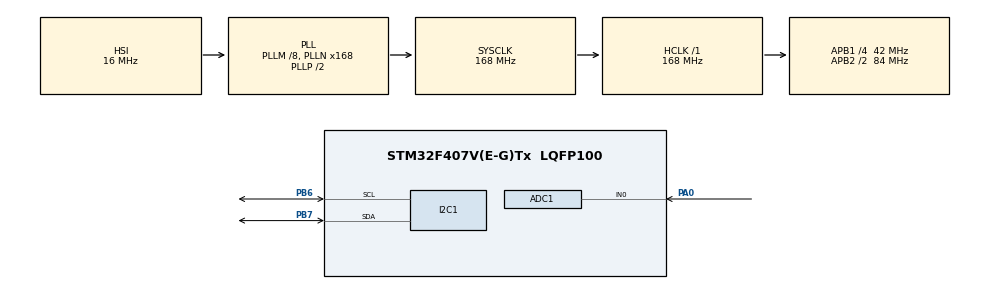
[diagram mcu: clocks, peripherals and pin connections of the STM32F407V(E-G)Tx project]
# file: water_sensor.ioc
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ADC1.Channel-0\#ChannelRegularConversion=ADC_CHANNEL_0
ADC1.NbrOfConversionFlag=1
ADC1.Rank-0\#ChannelRegularConversion=1
ADC1.SamplingTime-0\#ChannelRegularConversion=ADC_SAMPLETIME_3CYCLES
ADC1.master=1
Mcu.Family=STM32F4
Mcu.Name=STM32F407V(E-G)Tx
Mcu.Package=LQFP100
NVIC.PriorityGroup=NVIC_PRIORITYGROUP_4
PA0-WKUP.Signal=ADCx_IN0
PA13.Mode=Serial_Wire
PA13.Signal=SYS_JTMS-SWDIO
PA14.Mode=Serial_Wire
PA14.Signal=SYS_JTCK-SWCLK
PB6.Mode=I2C
PB6.Signal=I2C1_SCL
PB7.Mode=I2C
PB7.Signal=I2C1_SDA
PH0-OSC_IN.Mode=HSE-External-Oscillator
PH0-OSC_IN.Signal=RCC_OSC_IN
PH1-OSC_OUT.Mode=HSE-External-Oscillator
PH1-OSC_OUT.Signal=RCC_OSC_OUT
ProjectManager.HeapSize=0x200
ProjectManager.StackSize=0x400
ProjectManager.TargetToolchain=STM32CubeIDE
RCC.48MHZClocksFreq_Value=84000000
RCC.AHBFreq_Value=168000000
RCC.APB1CLKDivider=RCC_HCLK_DIV4
RCC.APB1Freq_Value=42000000
RCC.APB1TimFreq_Value=84000000
RCC.APB2CLKDivider=RCC_HCLK_DIV2
RCC.APB2Freq_Value=84000000
RCC.APB2TimFreq_Value=168000000
RCC.CortexFreq_Value=168000000
RCC.HCLKFreq_Value=168000000
RCC.HSE_VALUE=25000000
RCC.HSI_VALUE=16000000
RCC.LSE_VALUE=32768
RCC.PLLM=8
RCC.PLLN=168
RCC.SYSCLKFreq_VALUE=168000000
RCC.SYSCLKSource=RCC_SYSCLKSOURCE_PLLCLK
RCC.VCOOutputFreq_Value=336000000
SH.ADCx_IN0.0=ADC1_IN0,IN0
board=custom

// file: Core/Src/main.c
/* USER CODE BEGIN Header */
/**
  ******************************************************************************
  * @file           : main.c
  * @brief          : Main program body
  ******************************************************************************
  * @attention
  *
  * Copyright (c) 2024 STMicroelectronics.
  * All rights reserved.
  *
  * This software is licensed under terms that can be found in the LICENSE file
  * in the root directory of this software component.
  * If no LICENSE file comes with this software, it is provided AS-IS.
  *
  ******************************************************************************
  */
/* USER CODE END Header */
#include "main.h"
#include "i2c-lcd.h"
#include <stdio.h>

ADC_HandleTypeDef hadc1;

I2C_HandleTypeDef hi2c1;

/* USER CODE BEGIN PV */
uint32_t adc_value = 0;  // Valeur convertie de l'ADC
float water_level = 0.0; // Niveau d'eau en pourcentage
char buffer[16];

/* USER CODE END PV */

void SystemClock_Config(void);
static void MX_GPIO_Init(void);
static void MX_ADC1_Init(void);
static void MX_I2C1_Init(void);

int main(void)
{

  /* MCU Configuration--------------------------------------------------------*/

  /* Reset of all peripherals, Initializes the Flash interface and the Systick. */
  HAL_Init();

  /* Configure the system clock */
  SystemClock_Config();

  /* Initialize all configured peripherals */
  MX_GPIO_Init();
  MX_ADC1_Init();
  MX_I2C1_Init();
  /* USER CODE BEGIN 2 */
  // Initialiser l'écran LCD I2C
  lcd_init();
  lcd_clear();
  lcd_put_cur(0, 0);
  lcd_send_string("Water Level:");

  // Démarrer l'ADC
  HAL_ADC_Start(&hadc1);

  /* USER CODE END 2 */

  /* Infinite loop */
  while (1)
  {

    /* USER CODE BEGIN 3 */
	  // Attendre que la conversion ADC soit terminée
	         if (HAL_ADC_PollForConversion(&hadc1, 1000) == HAL_OK)
	         {
	             // Lire la valeur de l'ADC
	             adc_value = HAL_ADC_GetValue(&hadc1);

	             // Conversion de la valeur ADC en niveau d'eau
	             // Supposons que l'ADC est sur 12 bits (valeur max = 4095)
	             // Et que la tension maximale du capteur est 3.3V correspondant au niveau d'eau maximum
	             water_level = ((float)adc_value / 4095.0) * 100.0; // Niveau d'eau en pourcentage
	             snprintf(buffer, sizeof(buffer), "%.2f %%", water_level); // Formater le texte
	             lcd_put_cur(1, 0); // Ligne suivante
	             lcd_send_string(buffer); // Affichage du pourcentage
	         }

	         // Petite pause avant la prochaine lecture
	         HAL_Delay(1000); // 1 seconde

  }
  /* USER CODE END 3 */
}

void SystemClock_Config(void)
{
  RCC_OscInitTypeDef RCC_OscInitStruct = {0};
  RCC_ClkInitTypeDef RCC_ClkInitStruct = {0};

  /** Configure the main internal regulator output voltage
  */
  __HAL_RCC_PWR_CLK_ENABLE();
  __HAL_PWR_VOLTAGESCALING_CONFIG(PWR_REGULATOR_VOLTAGE_SCALE1);

  /** Initializes the RCC Oscillators according to the specified parameters
  * in the RCC_OscInitTypeDef structure.
  */
  RCC_OscInitStruct.OscillatorType = RCC_OSCILLATORTYPE_HSI;
  RCC_OscInitStruct.HSIState = RCC_HSI_ON;
  RCC_OscInitStruct.HSICalibrationValue = RCC_HSICALIBRATION_DEFAULT;
  RCC_OscInitStruct.PLL.PLLState = RCC_PLL_ON;
  RCC_OscInitStruct.PLL.PLLSource = RCC_PLLSOURCE_HSI;
  RCC_OscInitStruct.PLL.PLLM = 8;
  RCC_OscInitStruct.PLL.PLLN = 168;
  RCC_OscInitStruct.PLL.PLLP = RCC_PLLP_DIV2;
  RCC_OscInitStruct.PLL.PLLQ = 4;
  if (HAL_RCC_OscConfig(&RCC_OscInitStruct) != HAL_OK)
  {
    Error_Handler();
  }

  /** Initializes the CPU, AHB and APB buses clocks
  */
  RCC_ClkInitStruct.ClockType = RCC_CLOCKTYPE_HCLK|RCC_CLOCKTYPE_SYSCLK
                              |RCC_CLOCKTYPE_PCLK1|RCC_CLOCKTYPE_PCLK2;
  RCC_ClkInitStruct.SYSCLKSource = RCC_SYSCLKSOURCE_PLLCLK;
  RCC_ClkInitStruct.AHBCLKDivider = RCC_SYSCLK_DIV1;
  RCC_ClkInitStruct.APB1CLKDivider = RCC_HCLK_DIV4;
  RCC_ClkInitStruct.APB2CLKDivider = RCC_HCLK_DIV2;

  if (HAL_RCC_ClockConfig(&RCC_ClkInitStruct, FLASH_LATENCY_5) != HAL_OK)
  {
    Error_Handler();
  }
}

static void MX_ADC1_Init(void)
{

  ADC_ChannelConfTypeDef sConfig = {0};

  /** Configure the global features of the ADC (Clock, Resolution, Data Alignment and number of conversion)
  */
  hadc1.Instance = ADC1;
  hadc1.Init.ClockPrescaler = ADC_CLOCK_SYNC_PCLK_DIV4;
  hadc1.Init.Resolution = ADC_RESOLUTION_12B;
  hadc1.Init.ScanConvMode = DISABLE;
  hadc1.Init.ContinuousConvMode = DISABLE;
  hadc1.Init.DiscontinuousConvMode = DISABLE;
  hadc1.Init.ExternalTrigConvEdge = ADC_EXTERNALTRIGCONVEDGE_NONE;
  hadc1.Init.ExternalTrigConv = ADC_SOFTWARE_START;
  hadc1.Init.DataAlign = ADC_DATAALIGN_RIGHT;
  hadc1.Init.NbrOfConversion = 1;
  hadc1.Init.DMAContinuousRequests = DISABLE;
  hadc1.Init.EOCSelection = ADC_EOC_SINGLE_CONV;
  if (HAL_ADC_Init(&hadc1) != HAL_OK)
  {
    Error_Handler();
  }

  /** Configure for the selected ADC regular channel its corresponding rank in the sequencer and its sample time.
  */
  sConfig.Channel = ADC_CHANNEL_0;
  sConfig.Rank = 1;
  sConfig.SamplingTime = ADC_SAMPLETIME_3CYCLES;
  if (HAL_ADC_ConfigChannel(&hadc1, &sConfig) != HAL_OK)
  {
    Error_Handler();
  }

}

static void MX_I2C1_Init(void)
{

  hi2c1.Instance = I2C1;
  hi2c1.Init.ClockSpeed = 100000;
  hi2c1.Init.DutyCycle = I2C_DUTYCYCLE_2;
  hi2c1.Init.OwnAddress1 = 0;
  hi2c1.Init.AddressingMode = I2C_ADDRESSINGMODE_7BIT;
  hi2c1.Init.DualAddressMode = I2C_DUALADDRESS_DISABLE;
  hi2c1.Init.OwnAddress2 = 0;
  hi2c1.Init.GeneralCallMode = I2C_GENERALCALL_DISABLE;
  hi2c1.Init.NoStretchMode = I2C_NOSTRETCH_DISABLE;
  if (HAL_I2C_Init(&hi2c1) != HAL_OK)
  {
    Error_Handler();
  }

}

static void MX_GPIO_Init(void)
{

  /* GPIO Ports Clock Enable */
  __HAL_RCC_GPIOH_CLK_ENABLE();
  __HAL_RCC_GPIOA_CLK_ENABLE();
  __HAL_RCC_GPIOB_CLK_ENABLE();

}

void Error_Handler(void)
{
  __disable_irq();
  while (1)
  {
  }
}
